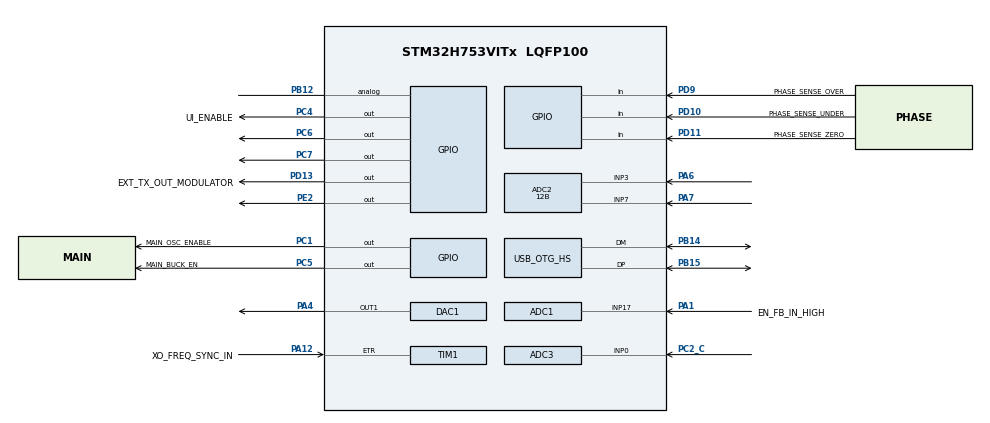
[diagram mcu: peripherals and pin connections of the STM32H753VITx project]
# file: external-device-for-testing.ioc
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ADC1.Channel-0\#ChannelRegularConversion=ADC_CHANNEL_17
ADC1.ClockPrescaler=ADC_CLOCK_SYNC_PCLK_DIV4
ADC1.ContinuousConvMode=DISABLE
ADC1.ConversionDataManagement=ADC_CONVERSIONDATA_DMA_CIRCULAR
ADC1.ExternalTrigConv=ADC_EXTERNALTRIG_T1_CC1
ADC1.ExternalTrigConvEdge=ADC_EXTERNALTRIGCONVEDGE_RISINGFALLING
ADC1.NbrOfConversionFlag=1
ADC1.OffsetNumber-0\#ChannelRegularConversion=ADC_OFFSET_NONE
ADC1.OffsetSignedSaturation-0\#ChannelRegularConversion=DISABLE
ADC1.Rank-0\#ChannelRegularConversion=1
ADC1.Resolution=ADC_RESOLUTION_12B
ADC1.SamplingTime-0\#ChannelRegularConversion=ADC_SAMPLETIME_1CYCLE_5
ADC1.master=1
ADC2.Channel-0\#ChannelRegularConversion=ADC_CHANNEL_7
ADC2.Channel-1\#ChannelRegularConversion=ADC_CHANNEL_3
ADC2.ClockPrescaler=ADC_CLOCK_SYNC_PCLK_DIV4
ADC2.ContinuousConvMode=ENABLE
ADC2.ConversionDataManagement=ADC_CONVERSIONDATA_DMA_CIRCULAR
ADC2.EOCSelection=ADC_EOC_SEQ_CONV
ADC2.NbrOfConversion=2
ADC2.NbrOfConversionFlag=1
ADC2.OffsetNumber-0\#ChannelRegularConversion=ADC_OFFSET_NONE
ADC2.OffsetNumber-1\#ChannelRegularConversion=ADC_OFFSET_NONE
ADC2.OffsetSignedSaturation-0\#ChannelRegularConversion=DISABLE
ADC2.Rank-0\#ChannelRegularConversion=1
ADC2.Rank-1\#ChannelRegularConversion=2
ADC2.Resolution=ADC_RESOLUTION_12B
ADC2.SamplingTime-0\#ChannelRegularConversion=ADC_SAMPLETIME_387CYCLES_5
ADC2.SamplingTime-1\#ChannelRegularConversion=ADC_SAMPLETIME_2CYCLES_5
ADC3.Channel-2\#ChannelRegularConversion=ADC_CHANNEL_0
ADC3.ClockPrescaler=ADC_CLOCK_SYNC_PCLK_DIV4
ADC3.NbrOfConversionFlag=1
ADC3.OffsetNumber-2\#ChannelRegularConversion=ADC_OFFSET_NONE
ADC3.OffsetSignedSaturation-2\#ChannelRegularConversion=DISABLE
ADC3.Rank-2\#ChannelRegularConversion=1
ADC3.SamplingTime-2\#ChannelRegularConversion=ADC_SAMPLETIME_1CYCLE_5
DAC1.DAC_Channel-DAC_OUT1=DAC_CHANNEL_1
Dma.ADC1.0.Direction=DMA_PERIPH_TO_MEMORY
Dma.ADC1.0.EventEnable=DISABLE
Dma.ADC1.0.FIFOMode=DMA_FIFOMODE_DISABLE
Dma.ADC1.0.Instance=DMA2_Stream4
Dma.ADC1.0.MemDataAlignment=DMA_MDATAALIGN_HALFWORD
Dma.ADC1.0.MemInc=DMA_MINC_ENABLE
Dma.ADC1.0.Mode=DMA_CIRCULAR
Dma.ADC1.0.PeriphDataAlignment=DMA_PDATAALIGN_HALFWORD
Dma.ADC1.0.PeriphInc=DMA_PINC_DISABLE
Dma.ADC1.0.Polarity=HAL_DMAMUX_REQ_GEN_RISING
Dma.ADC1.0.Priority=DMA_PRIORITY_LOW
Dma.ADC1.0.RequestNumber=1
Dma.ADC1.0.SignalID=NONE
Dma.ADC1.0.SyncEnable=DISABLE
Dma.ADC1.0.SyncPolarity=HAL_DMAMUX_SYNC_NO_EVENT
Dma.ADC1.0.SyncRequestNumber=1
Dma.ADC1.0.SyncSignalID=NONE
Dma.ADC2.1.Direction=DMA_PERIPH_TO_MEMORY
Dma.ADC2.1.EventEnable=DISABLE
Dma.ADC2.1.FIFOMode=DMA_FIFOMODE_DISABLE
Dma.ADC2.1.Instance=DMA2_Stream3
Dma.ADC2.1.MemDataAlignment=DMA_MDATAALIGN_HALFWORD
Dma.ADC2.1.MemInc=DMA_MINC_ENABLE
Dma.ADC2.1.Mode=DMA_CIRCULAR
Dma.ADC2.1.PeriphDataAlignment=DMA_PDATAALIGN_HALFWORD
Dma.ADC2.1.PeriphInc=DMA_PINC_DISABLE
Dma.ADC2.1.Polarity=HAL_DMAMUX_REQ_GEN_RISING
Dma.ADC2.1.Priority=DMA_PRIORITY_LOW
Dma.ADC2.1.RequestNumber=1
Dma.ADC2.1.SignalID=NONE
Dma.ADC2.1.SyncEnable=DISABLE
Dma.ADC2.1.SyncPolarity=HAL_DMAMUX_SYNC_NO_EVENT
Dma.ADC2.1.SyncRequestNumber=1
Dma.ADC2.1.SyncSignalID=NONE
Dma.Request0=ADC1
Dma.Request1=ADC2
FREERTOS.Tasks01=defaultTask,24,260,StartDefaultTask,Default,NULL,Dynamic,NULL,NULL
FREERTOS.configCHECK_FOR_STACK_OVERFLOW=1
FREERTOS.configMINIMAL_STACK_SIZE=260
FREERTOS.configTOTAL_HEAP_SIZE=53000
FREERTOS.configUSE_IDLE_HOOK=1
FREERTOS.configUSE_NEWLIB_REENTRANT=1
Mcu.Family=STM32H7
Mcu.Name=STM32H753VITx
Mcu.Package=LQFP100
NVIC.DMA2_Stream3_IRQn=true\:5\:0\:true\:false\:true\:false\:false\:true\:true
NVIC.DMA2_Stream4_IRQn=true\:5\:0\:true\:false\:true\:false\:false\:true\:true
NVIC.OTG_HS_IRQn=true\:5\:0\:false\:false\:true\:true\:true\:true\:true
NVIC.PVD_AVD_IRQn=true\:5\:0\:false\:false\:true\:true\:true\:true\:true
NVIC.PriorityGroup=NVIC_PRIORITYGROUP_4
NVIC.RTC_WKUP_IRQn=true\:5\:0\:false\:false\:true\:true\:true\:true\:true
NVIC.TIM1_BRK_IRQn=true\:5\:0\:false\:false\:true\:true\:true\:true\:true
NVIC.TIM1_CC_IRQn=true\:5\:0\:false\:false\:true\:true\:true\:true\:true
NVIC.TIM1_TRG_COM_IRQn=true\:5\:0\:false\:false\:true\:true\:true\:true\:true
NVIC.TIM1_UP_IRQn=true\:5\:0\:false\:false\:true\:true\:true\:true\:true
NVIC.TIM6_DAC_IRQn=true\:5\:0\:false\:false\:true\:true\:true\:true\:true
NVIC.TIM7_IRQn=true\:5\:0\:false\:false\:true\:true\:true\:true\:true
PA1.GPIO_Label=EN_FB_IN_HIGH
PA1.Mode=IN17-Single-Ended
PA1.Signal=ADC1_INP17
PA12.GPIO_Label=XO_FREQ_SYNC_IN
PA12.Signal=S_TIM1_ETR
PA13\ (JTMS/SWDIO).GPIO_Label=SYS_JTMS-SWDIO
PA13\ (JTMS/SWDIO).Mode=Serial_Wire
PA13\ (JTMS/SWDIO).Signal=DEBUG_JTMS-SWDIO
PA14\ (JTCK/SWCLK).GPIO_Label=SYS_JTCK-SWCLK
PA14\ (JTCK/SWCLK).Mode=Serial_Wire
PA14\ (JTCK/SWCLK).Signal=DEBUG_JTCK-SWCLK
PA4.Signal=COMP_DAC11_group
PA6.Signal=ADCx_INP3
PA7.Signal=ADCx_INP7
PB12.Signal=GPIO_Analog
PB14.GPIO_Speed=GPIO_SPEED_FREQ_VERY_HIGH
PB14.Mode=Device_Only_FS
PB14.Signal=USB_OTG_HS_DM
PB15.GPIO_Speed=GPIO_SPEED_FREQ_VERY_HIGH
PB15.Mode=Device_Only_FS
PB15.Signal=USB_OTG_HS_DP
PC1.GPIO_Label=MAIN_OSC_ENABLE
PC1.PinState=GPIO_PIN_SET
PC1.Signal=GPIO_Output
PC14-OSC32_IN\ (OSC32_IN).Mode=LSE-External-Oscillator
PC14-OSC32_IN\ (OSC32_IN).Signal=RCC_OSC32_IN
PC15-OSC32_OUT\ (OSC32_OUT).Mode=LSE-External-Oscillator
PC15-OSC32_OUT\ (OSC32_OUT).Signal=RCC_OSC32_OUT
PC2_C.Mode=IN0-Single-Ended
PC2_C.Signal=ADC3_INP0
PC4.GPIO_Label=UI_ENABLE
PC4.Signal=GPIO_Output
PC5.GPIO_Label=MAIN_BUCK_EN
PC5.Signal=GPIO_Output
PC6.Signal=GPIO_Output
PC7.Signal=GPIO_Output
PD10.GPIO_Label=PHASE_SENSE_UNDER
PD10.Signal=GPIO_Input
PD11.GPIO_Label=PHASE_SENSE_ZERO
PD11.Signal=GPIO_Input
PD13.GPIO_Label=EXT_TX_OUT_MODULATOR
PD13.Signal=GPIO_Output
PD9.GPIO_Label=PHASE_SENSE_OVER
PD9.Signal=GPIO_Input
PE2.Signal=GPIO_Output
PH0-OSC_IN\ (PH0).Mode=HSE-External-Oscillator
PH0-OSC_IN\ (PH0).Signal=RCC_OSC_IN
PH1-OSC_OUT\ (PH1).Mode=HSE-External-Oscillator
PH1-OSC_OUT\ (PH1).Signal=RCC_OSC_OUT
ProjectManager.HeapSize=0x200
ProjectManager.StackSize=0x1000
ProjectManager.TargetToolchain=STM32CubeIDE
RCC.ADCFreq_Value=48000000
RCC.APB1Freq_Value=36000000
RCC.APB2Freq_Value=72000000
RCC.APB3Freq_Value=72000000
RCC.APB4Freq_Value=72000000
RCC.CortexFreq_Value=72000000
RCC.D2PPRE1=RCC_APB1_DIV2
RCC.DIVM1=4
RCC.DIVM2=4
RCC.DIVN1=144
RCC.DIVN2=144
RCC.DIVP1=4
RCC.DIVP2=6
RCC.DIVQ1=6
RCC.DIVQ2=8
RCC.HCLKFreq_Value=72000000
RCC.HSE_VALUE=8000000
RCC.PLL2FRACN=0
RCC.PLL3FRACN=0
RCC.PLLFRACN=0
RCC.PLLSourceVirtual=RCC_PLLSOURCE_HSE
RCC.SYSCLKFreq_VALUE=72000000
RCC.SYSCLKSource=RCC_SYSCLKSOURCE_PLLCLK
RCC.Tim2Mul=1
RCC.USART16CLockSelection=RCC_USART16CLKSOURCE_PLL2
RCC.USBFreq_Value=48000000
SH.ADCx_INP3.0=ADC2_INP3,IN3-Single-Ended
SH.ADCx_INP7.0=ADC2_INP7,IN7-Single-Ended
SH.COMP_DAC11_group.0=DAC1_OUT1,DAC_OUT1
SH.S_TIM1_ETR.0=TIM1_ETR,TriggerSource_ETR
TIM1.AutoReloadPreload=TIM_AUTORELOAD_PRELOAD_ENABLE
TIM1.Channel-Output\ Compare1\ No\ Output=TIM_CHANNEL_1
TIM1.OC1Preload=ENABLE
TIM1.OCMode_1=TIM_OCMODE_TOGGLE
TIM1.Period=31
TIM1.Pulse-Output\ Compare1\ No\ Output=16
TIM1.TIM_MasterOutputTrigger=TIM_TRGO_OC1REF
TIM1.TIM_MasterSlaveMode=TIM_MASTERSLAVEMODE_ENABLE
TIM2.AutoReloadPreload=TIM_AUTORELOAD_PRELOAD_ENABLE
TIM2.Channel-PWM\ Generation4\ CH4=TIM_CHANNEL_4
TIM2.Period=100
TIM2.Prescaler=36
TIM2.TIM_MasterOutputTrigger=TIM_TRGO_UPDATE
TIM5.AutoReloadPreload=TIM_AUTORELOAD_PRELOAD_ENABLE
TIM5.Period=10
TIM5.Prescaler=36
TIM7.Period=10000
TIM7.Prescaler=4
USB_DEVICE.APP_RX_DATA_SIZE-CDC_HS=2048
USB_DEVICE.APP_TX_DATA_SIZE-CDC_HS=2048
USB_DEVICE.CLASS_NAME_HS=CDC
USB_DEVICE.VirtualMode-CDC_HS=Cdc
USB_DEVICE.VirtualModeHS=Cdc_HS
USB_OTG_HS.VirtualMode-Device_Only_FS=Device_Only_FS
USB_OTG_HS.dma_enable-Device_Only_FS=DISABLE
VP_FREERTOS_VS_CMSIS_V2.Mode=CMSIS_V2
VP_MEMORYMAP_VS_MEMORYMAP.Mode=CurAppReg
VP_RTC_VS_RTC_Activate.Mode=RTC_Enabled
VP_RTC_VS_RTC_Calendar.Mode=RTC_Calendar
VP_RTC_VS_RTC_WakeUp_intern.Mode=WakeUp
VP_TIM1_VS_ControllerModeClock.Mode=Clock Mode
VP_TIM1_VS_no_output1.Mode=Output Compare1 No Output
VP_TIM2_VS_ClockSourceINT.Mode=Internal
VP_TIM5_VS_ClockSourceINT.Mode=Internal
VP_TIM6_VS_ClockSourceINT.Mode=Enable_Timer
VP_TIM7_VS_ClockSourceINT.Mode=Enable_Timer
VP_USB_DEVICE_VS_USB_DEVICE_CDC_HS.Mode=CDC_HS
board=custom

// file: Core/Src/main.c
/* USER CODE BEGIN Header */
/**
 ******************************************************************************
 * @file           : main.c
 * @brief          : Main program body
 ******************************************************************************
 * @attention
 *
 * Copyright (c) 2025 STMicroelectronics.
 * All rights reserved.
 *
 * This software is licensed under terms that can be found in the LICENSE file
 * in the root directory of this software component.
 * If no LICENSE file comes with this software, it is provided AS-IS.
 *
 ******************************************************************************
 */
/* USER CODE END Header */
#include "main.h"
#include "cmsis_os.h"
#include "usb_device.h"

/* USER CODE BEGIN Includes */
#include "vlapMain.h"
/* USER CODE END Includes */

ADC_HandleTypeDef hadc1;
ADC_HandleTypeDef hadc2;
ADC_HandleTypeDef hadc3;
DMA_HandleTypeDef hdma_adc1;
DMA_HandleTypeDef hdma_adc2;

DAC_HandleTypeDef hdac1;

RTC_HandleTypeDef hrtc;

TIM_HandleTypeDef htim1;
TIM_HandleTypeDef htim2;
TIM_HandleTypeDef htim5;
TIM_HandleTypeDef htim6;
TIM_HandleTypeDef htim7;

/* Definitions for defaultTask */
osThreadId_t defaultTaskHandle;
const osThreadAttr_t defaultTask_attributes = {
  .name = "defaultTask",
  .stack_size = 260 * 4,
  .priority = (osPriority_t) osPriorityNormal,
};

void SystemClock_Config(void);
static void MX_GPIO_Init(void);
static void MX_DMA_Init(void);
static void MX_RTC_Init(void);
static void MX_ADC1_Init(void);
static void MX_TIM1_Init(void);
static void MX_TIM2_Init(void);
static void MX_TIM5_Init(void);
static void MX_TIM6_Init(void);
static void MX_TIM7_Init(void);
static void MX_ADC3_Init(void);
static void MX_ADC2_Init(void);
static void MX_DAC1_Init(void);
void StartDefaultTask(void *argument);

/* USER CODE BEGIN 0 */
uint8_t mainFirstTimeAfterJlinkProgramming;
/* USER CODE END 0 */

int main(void)
{

  /* USER CODE BEGIN 1 */
	// We need to enable the external 27.12Mhz generator first before we init clocks
//	SCB->VTOR = FLASH_BASE | (0x0000C000U & (uint32_t) 0x1FFFFF80); /* Vector Table Relocation in Internal SRAM */
	HAL_Init();
	MX_GPIO_Init();
  /* USER CODE END 1 */

  /* MCU Configuration--------------------------------------------------------*/

  /* Reset of all peripherals, Initializes the Flash interface and the Systick. */
  HAL_Init();

  /* Configure the system clock */
  SystemClock_Config();

  /* Initialize all configured peripherals */
  MX_GPIO_Init();
  MX_DMA_Init();
  MX_RTC_Init();
  MX_ADC1_Init();
  MX_TIM1_Init();
  MX_TIM2_Init();
  MX_TIM5_Init();
  MX_TIM6_Init();
  MX_TIM7_Init();
  MX_ADC3_Init();
  MX_ADC2_Init();
  MX_DAC1_Init();
  /* USER CODE BEGIN 2 */

	protocolappPowerUpInit();

	vlapMainBusy = 1;
	vlapMainSetupHardware(mainFirstTimeAfterJlinkProgramming);

	mainFirstTimeAfterJlinkProgramming = 0;

	// create vlapMainTask
	//
	xTaskCreate(vlapMain, vlapMainName, vlapMainSTACK_SIZE, NULL,
			vlapMainPriority, (TaskHandle_t*) NULL);

	// Clear the reset reason for coming
	__HAL_RCC_CLEAR_RESET_FLAGS();

  /* USER CODE END 2 */

  /* Init scheduler */
  osKernelInitialize();

  /* Create the thread(s) */
  /* creation of defaultTask */
  defaultTaskHandle = osThreadNew(StartDefaultTask, NULL, &defaultTask_attributes);

  /* Start scheduler */
  osKernelStart();

  /* We should never get here as control is now taken by the scheduler */

  /* Infinite loop */
	while (1) {

	}
}

void SystemClock_Config(void)
{
  RCC_OscInitTypeDef RCC_OscInitStruct = {0};
  RCC_ClkInitTypeDef RCC_ClkInitStruct = {0};

  /** Supply configuration update enable
  */
  HAL_PWREx_ConfigSupply(PWR_LDO_SUPPLY);

  /** Configure the main internal regulator output voltage
  */
  __HAL_PWR_VOLTAGESCALING_CONFIG(PWR_REGULATOR_VOLTAGE_SCALE3);

  while(!__HAL_PWR_GET_FLAG(PWR_FLAG_VOSRDY)) {}

  /** Initializes the RCC Oscillators according to the specified parameters
  * in the RCC_OscInitTypeDef structure.
  */
  RCC_OscInitStruct.OscillatorType = RCC_OSCILLATORTYPE_LSI|RCC_OSCILLATORTYPE_HSE;
  RCC_OscInitStruct.HSEState = RCC_HSE_ON;
  RCC_OscInitStruct.LSIState = RCC_LSI_ON;
  RCC_OscInitStruct.PLL.PLLState = RCC_PLL_ON;
  RCC_OscInitStruct.PLL.PLLSource = RCC_PLLSOURCE_HSE;
  RCC_OscInitStruct.PLL.PLLM = 4;
  RCC_OscInitStruct.PLL.PLLN = 144;
  RCC_OscInitStruct.PLL.PLLP = 4;
  RCC_OscInitStruct.PLL.PLLQ = 6;
  RCC_OscInitStruct.PLL.PLLR = 2;
  RCC_OscInitStruct.PLL.PLLRGE = RCC_PLL1VCIRANGE_1;
  RCC_OscInitStruct.PLL.PLLVCOSEL = RCC_PLL1VCOWIDE;
  RCC_OscInitStruct.PLL.PLLFRACN = 0;
  if (HAL_RCC_OscConfig(&RCC_OscInitStruct) != HAL_OK)
  {
    Error_Handler();
  }

  /** Initializes the CPU, AHB and APB buses clocks
  */
  RCC_ClkInitStruct.ClockType = RCC_CLOCKTYPE_HCLK|RCC_CLOCKTYPE_SYSCLK
                              |RCC_CLOCKTYPE_PCLK1|RCC_CLOCKTYPE_PCLK2
                              |RCC_CLOCKTYPE_D3PCLK1|RCC_CLOCKTYPE_D1PCLK1;
  RCC_ClkInitStruct.SYSCLKSource = RCC_SYSCLKSOURCE_PLLCLK;
  RCC_ClkInitStruct.SYSCLKDivider = RCC_SYSCLK_DIV1;
  RCC_ClkInitStruct.AHBCLKDivider = RCC_HCLK_DIV1;
  RCC_ClkInitStruct.APB3CLKDivider = RCC_APB3_DIV1;
  RCC_ClkInitStruct.APB1CLKDivider = RCC_APB1_DIV2;
  RCC_ClkInitStruct.APB2CLKDivider = RCC_APB2_DIV1;
  RCC_ClkInitStruct.APB4CLKDivider = RCC_APB4_DIV1;

  if (HAL_RCC_ClockConfig(&RCC_ClkInitStruct, FLASH_LATENCY_1) != HAL_OK)
  {
    Error_Handler();
  }
}

static void MX_ADC1_Init(void)
{

  ADC_MultiModeTypeDef multimode = {0};
  ADC_ChannelConfTypeDef sConfig = {0};

  /** Common config
  */
  hadc1.Instance = ADC1;
  hadc1.Init.ClockPrescaler = ADC_CLOCK_SYNC_PCLK_DIV4;
  hadc1.Init.Resolution = ADC_RESOLUTION_12B;
  hadc1.Init.ScanConvMode = ADC_SCAN_DISABLE;
  hadc1.Init.EOCSelection = ADC_EOC_SINGLE_CONV;
  hadc1.Init.LowPowerAutoWait = DISABLE;
  hadc1.Init.ContinuousConvMode = DISABLE;
  hadc1.Init.NbrOfConversion = 1;
  hadc1.Init.DiscontinuousConvMode = DISABLE;
  hadc1.Init.ExternalTrigConv = ADC_EXTERNALTRIG_T1_CC1;
  hadc1.Init.ExternalTrigConvEdge = ADC_EXTERNALTRIGCONVEDGE_RISINGFALLING;
  hadc1.Init.ConversionDataManagement = ADC_CONVERSIONDATA_DMA_CIRCULAR;
  hadc1.Init.Overrun = ADC_OVR_DATA_PRESERVED;
  hadc1.Init.LeftBitShift = ADC_LEFTBITSHIFT_NONE;
  hadc1.Init.OversamplingMode = DISABLE;
  hadc1.Init.Oversampling.Ratio = 1;
  if (HAL_ADC_Init(&hadc1) != HAL_OK)
  {
    Error_Handler();
  }

  /** Configure the ADC multi-mode
  */
  multimode.Mode = ADC_MODE_INDEPENDENT;
  if (HAL_ADCEx_MultiModeConfigChannel(&hadc1, &multimode) != HAL_OK)
  {
    Error_Handler();
  }

  /** Configure Regular Channel
  */
  sConfig.Channel = ADC_CHANNEL_17;
  sConfig.Rank = ADC_REGULAR_RANK_1;
  sConfig.SamplingTime = ADC_SAMPLETIME_1CYCLE_5;
  sConfig.SingleDiff = ADC_SINGLE_ENDED;
  sConfig.OffsetNumber = ADC_OFFSET_NONE;
  sConfig.Offset = 0;
  sConfig.OffsetSignedSaturation = DISABLE;
  if (HAL_ADC_ConfigChannel(&hadc1, &sConfig) != HAL_OK)
  {
    Error_Handler();
  }

}

static void MX_ADC2_Init(void)
{

  ADC_ChannelConfTypeDef sConfig = {0};

  /** Common config
  */
  hadc2.Instance = ADC2;
  hadc2.Init.ClockPrescaler = ADC_CLOCK_SYNC_PCLK_DIV4;
  hadc2.Init.Resolution = ADC_RESOLUTION_12B;
  hadc2.Init.ScanConvMode = ADC_SCAN_ENABLE;
  hadc2.Init.EOCSelection = ADC_EOC_SEQ_CONV;
  hadc2.Init.LowPowerAutoWait = DISABLE;
  hadc2.Init.ContinuousConvMode = ENABLE;
  hadc2.Init.NbrOfConversion = 2;
  hadc2.Init.DiscontinuousConvMode = DISABLE;
  hadc2.Init.ExternalTrigConv = ADC_SOFTWARE_START;
  hadc2.Init.ExternalTrigConvEdge = ADC_EXTERNALTRIGCONVEDGE_NONE;
  hadc2.Init.ConversionDataManagement = ADC_CONVERSIONDATA_DMA_CIRCULAR;
  hadc2.Init.Overrun = ADC_OVR_DATA_PRESERVED;
  hadc2.Init.LeftBitShift = ADC_LEFTBITSHIFT_NONE;
  hadc2.Init.OversamplingMode = DISABLE;
  hadc2.Init.Oversampling.Ratio = 1;
  if (HAL_ADC_Init(&hadc2) != HAL_OK)
  {
    Error_Handler();
  }

  /** Configure Regular Channel
  */
  sConfig.Channel = ADC_CHANNEL_7;
  sConfig.Rank = ADC_REGULAR_RANK_1;
  sConfig.SamplingTime = ADC_SAMPLETIME_387CYCLES_5;
  sConfig.SingleDiff = ADC_SINGLE_ENDED;
  sConfig.OffsetNumber = ADC_OFFSET_NONE;
  sConfig.Offset = 0;
  sConfig.OffsetSignedSaturation = DISABLE;
  if (HAL_ADC_ConfigChannel(&hadc2, &sConfig) != HAL_OK)
  {
    Error_Handler();
  }

  /** Configure Regular Channel
  */
  sConfig.Channel = ADC_CHANNEL_3;
  sConfig.Rank = ADC_REGULAR_RANK_2;
  sConfig.SamplingTime = ADC_SAMPLETIME_2CYCLES_5;
  if (HAL_ADC_ConfigChannel(&hadc2, &sConfig) != HAL_OK)
  {
    Error_Handler();
  }

}

static void MX_ADC3_Init(void)
{

  ADC_ChannelConfTypeDef sConfig = {0};

  /** Common config
  */
  hadc3.Instance = ADC3;
  hadc3.Init.ClockPrescaler = ADC_CLOCK_ASYNC_DIV1;
  hadc3.Init.ScanConvMode = ADC_SCAN_DISABLE;
  hadc3.Init.EOCSelection = ADC_EOC_SINGLE_CONV;
  hadc3.Init.LowPowerAutoWait = DISABLE;
  hadc3.Init.ContinuousConvMode = DISABLE;
  hadc3.Init.NbrOfConversion = 1;
  hadc3.Init.DiscontinuousConvMode = DISABLE;
  hadc3.Init.ExternalTrigConv = ADC_SOFTWARE_START;
  hadc3.Init.ExternalTrigConvEdge = ADC_EXTERNALTRIGCONVEDGE_NONE;
  hadc3.Init.ConversionDataManagement = ADC_CONVERSIONDATA_DR;
  hadc3.Init.Overrun = ADC_OVR_DATA_PRESERVED;
  hadc3.Init.LeftBitShift = ADC_LEFTBITSHIFT_NONE;
  hadc3.Init.OversamplingMode = DISABLE;
  hadc3.Init.Oversampling.Ratio = 1;
  if (HAL_ADC_Init(&hadc3) != HAL_OK)
  {
    Error_Handler();
  }

  /** Configure Regular Channel
  */
  sConfig.Channel = ADC_CHANNEL_0;
  sConfig.Rank = ADC_REGULAR_RANK_1;
  sConfig.SamplingTime = ADC_SAMPLETIME_1CYCLE_5;
  sConfig.SingleDiff = ADC_SINGLE_ENDED;
  sConfig.OffsetNumber = ADC_OFFSET_NONE;
  sConfig.Offset = 0;
  sConfig.OffsetSignedSaturation = DISABLE;
  if (HAL_ADC_ConfigChannel(&hadc3, &sConfig) != HAL_OK)
  {
    Error_Handler();
  }

}

static void MX_DAC1_Init(void)
{

  DAC_ChannelConfTypeDef sConfig = {0};

  /** DAC Initialization
  */
  hdac1.Instance = DAC1;
  if (HAL_DAC_Init(&hdac1) != HAL_OK)
  {
    Error_Handler();
  }

  /** DAC channel OUT1 config
  */
  sConfig.DAC_SampleAndHold = DAC_SAMPLEANDHOLD_DISABLE;
  sConfig.DAC_Trigger = DAC_TRIGGER_NONE;
  sConfig.DAC_OutputBuffer = DAC_OUTPUTBUFFER_ENABLE;
  sConfig.DAC_ConnectOnChipPeripheral = DAC_CHIPCONNECT_DISABLE;
  sConfig.DAC_UserTrimming = DAC_TRIMMING_FACTORY;
  if (HAL_DAC_ConfigChannel(&hdac1, &sConfig, DAC_CHANNEL_1) != HAL_OK)
  {
    Error_Handler();
  }

}

static void MX_RTC_Init(void)
{

  RTC_TimeTypeDef sTime = {0};
  RTC_DateTypeDef sDate = {0};

  /** Initialize RTC Only
  */
  hrtc.Instance = RTC;
  hrtc.Init.HourFormat = RTC_HOURFORMAT_24;
  hrtc.Init.AsynchPrediv = 127;
  hrtc.Init.SynchPrediv = 255;
  hrtc.Init.OutPut = RTC_OUTPUT_DISABLE;
  hrtc.Init.OutPutPolarity = RTC_OUTPUT_POLARITY_HIGH;
  hrtc.Init.OutPutType = RTC_OUTPUT_TYPE_OPENDRAIN;
  hrtc.Init.OutPutRemap = RTC_OUTPUT_REMAP_NONE;
  if (HAL_RTC_Init(&hrtc) != HAL_OK)
  {
    Error_Handler();
  }

  /** Initialize RTC and set the Time and Date
  */
  sTime.Hours = 0x0;
  sTime.Minutes = 0x0;
  sTime.Seconds = 0x0;
  sTime.DayLightSaving = RTC_DAYLIGHTSAVING_NONE;
  sTime.StoreOperation = RTC_STOREOPERATION_RESET;
  if (HAL_RTC_SetTime(&hrtc, &sTime, RTC_FORMAT_BCD) != HAL_OK)
  {
    Error_Handler();
  }
  sDate.WeekDay = RTC_WEEKDAY_MONDAY;
  sDate.Month = RTC_MONTH_JANUARY;
  sDate.Date = 0x1;
  sDate.Year = 0x0;

  if (HAL_RTC_SetDate(&hrtc, &sDate, RTC_FORMAT_BCD) != HAL_OK)
  {
    Error_Handler();
  }

  /** Enable the WakeUp
  */
  if (HAL_RTCEx_SetWakeUpTimer_IT(&hrtc, 0, RTC_WAKEUPCLOCK_RTCCLK_DIV16) != HAL_OK)
  {
    Error_Handler();
  }

}

static void MX_TIM1_Init(void)
{

  TIM_SlaveConfigTypeDef sSlaveConfig = {0};
  TIM_MasterConfigTypeDef sMasterConfig = {0};
  TIM_OC_InitTypeDef sConfigOC = {0};
  TIM_BreakDeadTimeConfigTypeDef sBreakDeadTimeConfig = {0};

  htim1.Instance = TIM1;
  htim1.Init.Prescaler = 0;
  htim1.Init.CounterMode = TIM_COUNTERMODE_UP;
  htim1.Init.Period = 31;
  htim1.Init.ClockDivision = TIM_CLOCKDIVISION_DIV1;
  htim1.Init.RepetitionCounter = 0;
  htim1.Init.AutoReloadPreload = TIM_AUTORELOAD_PRELOAD_ENABLE;
  if (HAL_TIM_Base_Init(&htim1) != HAL_OK)
  {
    Error_Handler();
  }
  if (HAL_TIM_OC_Init(&htim1) != HAL_OK)
  {
    Error_Handler();
  }
  sSlaveConfig.SlaveMode = TIM_SLAVEMODE_EXTERNAL1;
  sSlaveConfig.InputTrigger = TIM_TS_ETRF;
  sSlaveConfig.TriggerPolarity = TIM_TRIGGERPOLARITY_NONINVERTED;
  sSlaveConfig.TriggerPrescaler = TIM_TRIGGERPRESCALER_DIV1;
  sSlaveConfig.TriggerFilter = 0;
  if (HAL_TIM_SlaveConfigSynchro(&htim1, &sSlaveConfig) != HAL_OK)
  {
    Error_Handler();
  }
  sMasterConfig.MasterOutputTrigger = TIM_TRGO_OC1REF;
  sMasterConfig.MasterOutputTrigger2 = TIM_TRGO2_RESET;
  sMasterConfig.MasterSlaveMode = TIM_MASTERSLAVEMODE_ENABLE;
  if (HAL_TIMEx_MasterConfigSynchronization(&htim1, &sMasterConfig) != HAL_OK)
  {
    Error_Handler();
  }
  sConfigOC.OCMode = TIM_OCMODE_TOGGLE;
  sConfigOC.Pulse = 16;
  sConfigOC.OCPolarity = TIM_OCPOLARITY_HIGH;
  sConfigOC.OCNPolarity = TIM_OCNPOLARITY_HIGH;
  sConfigOC.OCFastMode = TIM_OCFAST_DISABLE;
  sConfigOC.OCIdleState = TIM_OCIDLESTATE_RESET;
  sConfigOC.OCNIdleState = TIM_OCNIDLESTATE_RESET;
  if (HAL_TIM_OC_ConfigChannel(&htim1, &sConfigOC, TIM_CHANNEL_1) != HAL_OK)
  {
    Error_Handler();
  }
  __HAL_TIM_ENABLE_OCxPRELOAD(&htim1, TIM_CHANNEL_1);
  sBreakDeadTimeConfig.OffStateRunMode = TIM_OSSR_DISABLE;
  sBreakDeadTimeConfig.OffStateIDLEMode = TIM_OSSI_DISABLE;
  sBreakDeadTimeConfig.LockLevel = TIM_LOCKLEVEL_OFF;
  sBreakDeadTimeConfig.DeadTime = 0;
  sBreakDeadTimeConfig.BreakState = TIM_BREAK_DISABLE;
  sBreakDeadTimeConfig.BreakPolarity = TIM_BREAKPOLARITY_HIGH;
  sBreakDeadTimeConfig.BreakFilter = 0;
  sBreakDeadTimeConfig.Break2State = TIM_BREAK2_DISABLE;
  sBreakDeadTimeConfig.Break2Polarity = TIM_BREAK2POLARITY_HIGH;
  sBreakDeadTimeConfig.Break2Filter = 0;
  sBreakDeadTimeConfig.AutomaticOutput = TIM_AUTOMATICOUTPUT_DISABLE;
  if (HAL_TIMEx_ConfigBreakDeadTime(&htim1, &sBreakDeadTimeConfig) != HAL_OK)
  {
    Error_Handler();
  }

}

static void MX_TIM2_Init(void)
{

  TIM_ClockConfigTypeDef sClockSourceConfig = {0};
  TIM_MasterConfigTypeDef sMasterConfig = {0};

  htim2.Instance = TIM2;
  htim2.Init.Prescaler = 36;
  htim2.Init.CounterMode = TIM_COUNTERMODE_UP;
  htim2.Init.Period = 100;
  htim2.Init.ClockDivision = TIM_CLOCKDIVISION_DIV1;
  htim2.Init.AutoReloadPreload = TIM_AUTORELOAD_PRELOAD_ENABLE;
  if (HAL_TIM_Base_Init(&htim2) != HAL_OK)
  {
    Error_Handler();
  }
  sClockSourceConfig.ClockSource = TIM_CLOCKSOURCE_INTERNAL;
  if (HAL_TIM_ConfigClockSource(&htim2, &sClockSourceConfig) != HAL_OK)
  {
    Error_Handler();
  }
  sMasterConfig.MasterOutputTrigger = TIM_TRGO_UPDATE;
  sMasterConfig.MasterSlaveMode = TIM_MASTERSLAVEMODE_DISABLE;
  if (HAL_TIMEx_MasterConfigSynchronization(&htim2, &sMasterConfig) != HAL_OK)
  {
    Error_Handler();
  }

}

static void MX_TIM5_Init(void)
{

  TIM_ClockConfigTypeDef sClockSourceConfig = {0};
  TIM_MasterConfigTypeDef sMasterConfig = {0};

  htim5.Instance = TIM5;
  htim5.Init.Prescaler = 36;
  htim5.Init.CounterMode = TIM_COUNTERMODE_UP;
  htim5.Init.Period = 10;
  htim5.Init.ClockDivision = TIM_CLOCKDIVISION_DIV1;
  htim5.Init.AutoReloadPreload = TIM_AUTORELOAD_PRELOAD_ENABLE;
  if (HAL_TIM_Base_Init(&htim5) != HAL_OK)
  {
    Error_Handler();
  }
  sClockSourceConfig.ClockSource = TIM_CLOCKSOURCE_INTERNAL;
  if (HAL_TIM_ConfigClockSource(&htim5, &sClockSourceConfig) != HAL_OK)
  {
    Error_Handler();
  }
  sMasterConfig.MasterOutputTrigger = TIM_TRGO_RESET;
  sMasterConfig.MasterSlaveMode = TIM_MASTERSLAVEMODE_DISABLE;
  if (HAL_TIMEx_MasterConfigSynchronization(&htim5, &sMasterConfig) != HAL_OK)
  {
    Error_Handler();
  }

}

static void MX_TIM6_Init(void)
{

  TIM_MasterConfigTypeDef sMasterConfig = {0};

  htim6.Instance = TIM6;
  htim6.Init.Prescaler = 0;
  htim6.Init.CounterMode = TIM_COUNTERMODE_UP;
  htim6.Init.Period = 65535;
  htim6.Init.AutoReloadPreload = TIM_AUTORELOAD_PRELOAD_DISABLE;
  if (HAL_TIM_Base_Init(&htim6) != HAL_OK)
  {
    Error_Handler();
  }
  sMasterConfig.MasterOutputTrigger = TIM_TRGO_RESET;
  sMasterConfig.MasterSlaveMode = TIM_MASTERSLAVEMODE_DISABLE;
  if (HAL_TIMEx_MasterConfigSynchronization(&htim6, &sMasterConfig) != HAL_OK)
  {
    Error_Handler();
  }

}

static void MX_TIM7_Init(void)
{

  TIM_MasterConfigTypeDef sMasterConfig = {0};

  htim7.Instance = TIM7;
  htim7.Init.Prescaler = 4;
  htim7.Init.CounterMode = TIM_COUNTERMODE_UP;
  htim7.Init.Period = 10000;
  htim7.Init.AutoReloadPreload = TIM_AUTORELOAD_PRELOAD_DISABLE;
  if (HAL_TIM_Base_Init(&htim7) != HAL_OK)
  {
    Error_Handler();
  }
  sMasterConfig.MasterOutputTrigger = TIM_TRGO_RESET;
  sMasterConfig.MasterSlaveMode = TIM_MASTERSLAVEMODE_DISABLE;
  if (HAL_TIMEx_MasterConfigSynchronization(&htim7, &sMasterConfig) != HAL_OK)
  {
    Error_Handler();
  }

}

static void MX_DMA_Init(void)
{

  /* DMA controller clock enable */
  __HAL_RCC_DMA2_CLK_ENABLE();

  /* DMA interrupt init */
  /* DMA2_Stream3_IRQn interrupt configuration */
  HAL_NVIC_SetPriority(DMA2_Stream3_IRQn, 5, 0);
  HAL_NVIC_EnableIRQ(DMA2_Stream3_IRQn);
  /* DMA2_Stream4_IRQn interrupt configuration */
  HAL_NVIC_SetPriority(DMA2_Stream4_IRQn, 5, 0);
  HAL_NVIC_EnableIRQ(DMA2_Stream4_IRQn);

}

static void MX_GPIO_Init(void)
{
  GPIO_InitTypeDef GPIO_InitStruct = {0};

  /* GPIO Ports Clock Enable */
  __HAL_RCC_GPIOE_CLK_ENABLE();
  __HAL_RCC_GPIOC_CLK_ENABLE();
  __HAL_RCC_GPIOH_CLK_ENABLE();
  __HAL_RCC_GPIOA_CLK_ENABLE();
  __HAL_RCC_GPIOB_CLK_ENABLE();
  __HAL_RCC_GPIOD_CLK_ENABLE();

  /*Configure GPIO pin Output Level */
  HAL_GPIO_WritePin(GPIOE, GPIO_PIN_2, GPIO_PIN_RESET);

  /*Configure GPIO pin Output Level */
  HAL_GPIO_WritePin(MAIN_OSC_ENABLE_GPIO_Port, MAIN_OSC_ENABLE_Pin, GPIO_PIN_SET);

  /*Configure GPIO pin Output Level */
  HAL_GPIO_WritePin(GPIOC, UI_ENABLE_Pin|MAIN_BUCK_EN_Pin|GPIO_PIN_6|GPIO_PIN_7, GPIO_PIN_RESET);

  /*Configure GPIO pin Output Level */
  HAL_GPIO_WritePin(EXT_TX_OUT_MODULATOR_GPIO_Port, EXT_TX_OUT_MODULATOR_Pin, GPIO_PIN_RESET);

  /*Configure GPIO pin : PE2 */
  GPIO_InitStruct.Pin = GPIO_PIN_2;
  GPIO_InitStruct.Mode = GPIO_MODE_OUTPUT_PP;
  GPIO_InitStruct.Pull = GPIO_NOPULL;
  GPIO_InitStruct.Speed = GPIO_SPEED_FREQ_LOW;
  HAL_GPIO_Init(GPIOE, &GPIO_InitStruct);

  /*Configure GPIO pins : MAIN_OSC_ENABLE_Pin UI_ENABLE_Pin MAIN_BUCK_EN_Pin PC6
                           PC7 */
  GPIO_InitStruct.Pin = MAIN_OSC_ENABLE_Pin|UI_ENABLE_Pin|MAIN_BUCK_EN_Pin|GPIO_PIN_6
                          |GPIO_PIN_7;
  GPIO_InitStruct.Mode = GPIO_MODE_OUTPUT_PP;
  GPIO_InitStruct.Pull = GPIO_NOPULL;
  GPIO_InitStruct.Speed = GPIO_SPEED_FREQ_LOW;
  HAL_GPIO_Init(GPIOC, &GPIO_InitStruct);

  /*Configure GPIO pin : PB12 */
  GPIO_InitStruct.Pin = GPIO_PIN_12;
  GPIO_InitStruct.Mode = GPIO_MODE_ANALOG;
  GPIO_InitStruct.Pull = GPIO_NOPULL;
  HAL_GPIO_Init(GPIOB, &GPIO_InitStruct);

  /*Configure GPIO pins : PHASE_SENSE_OVER_Pin PHASE_SENSE_UNDER_Pin PHASE_SENSE_ZERO_Pin */
  GPIO_InitStruct.Pin = PHASE_SENSE_OVER_Pin|PHASE_SENSE_UNDER_Pin|PHASE_SENSE_ZERO_Pin;
  GPIO_InitStruct.Mode = GPIO_MODE_INPUT;
  GPIO_InitStruct.Pull = GPIO_NOPULL;
  HAL_GPIO_Init(GPIOD, &GPIO_InitStruct);

  /*Configure GPIO pin : EXT_TX_OUT_MODULATOR_Pin */
  GPIO_InitStruct.Pin = EXT_TX_OUT_MODULATOR_Pin;
  GPIO_InitStruct.Mode = GPIO_MODE_OUTPUT_PP;
  GPIO_InitStruct.Pull = GPIO_NOPULL;
  GPIO_InitStruct.Speed = GPIO_SPEED_FREQ_LOW;
  HAL_GPIO_Init(EXT_TX_OUT_MODULATOR_GPIO_Port, &GPIO_InitStruct);

}

/* USER CODE BEGIN 4 */
void HAL_TIM_PeriodElapsedCallback(TIM_HandleTypeDef *htim)
{
  /* USER CODE BEGIN Callback 0 */

  /* USER CODE END Callback 0 */
  if (htim->Instance == TIM6) {
    vmicmodemTim6Isr();
  }
  /* USER CODE BEGIN Callback 1 */

  /* USER CODE END Callback 1 */
}
/* USER CODE END 4 */

void StartDefaultTask(void *argument)
{
  /* init code for USB_DEVICE */
  MX_USB_DEVICE_Init();
	for (;;) {
		osDelay(1);
	}
}

void Error_Handler(void)
{
	__disable_irq();
	while (1) {
	}
}

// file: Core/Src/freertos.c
/* USER CODE BEGIN Header */
/**
  ******************************************************************************
  * File Name          : freertos.c
  * Description        : Code for freertos applications
  ******************************************************************************
  * @attention
  *
  * Copyright (c) 2025 STMicroelectronics.
  * All rights reserved.
  *
  * This software is licensed under terms that can be found in the LICENSE file
  * in the root directory of this software component.
  * If no LICENSE file comes with this software, it is provided AS-IS.
  *
  ******************************************************************************
  */
/* USER CODE END Header */

#include "FreeRTOS.h"
#include "task.h"
#include "main.h"

/* Hook prototypes */
void vApplicationIdleHook(void);
void vApplicationStackOverflowHook(xTaskHandle xTask, signed char *pcTaskName);

/* USER CODE BEGIN 2 */
void vApplicationIdleHook( void )
{
   /* vApplicationIdleHook() will only be called if configUSE_IDLE_HOOK is set
   to 1 in FreeRTOSConfig.h. It will be called on each iteration of the idle
   task. It is essential that code added to this hook function never attempts
   to block in any way (for example, call xQueueReceive() with a block time
   specified, or call vTaskDelay()). If the application makes use of the
   vTaskDelete() API function (as this demo application does) then it is also
   important that vApplicationIdleHook() is permitted to return to its calling
   function, because it is the responsibility of the idle task to clean up
   memory allocated by the kernel to any task that has since been deleted. */
}
/* USER CODE END 2 */

/* USER CODE BEGIN 4 */
void vApplicationStackOverflowHook(xTaskHandle xTask, signed char *pcTaskName)
{
   /* Run time stack overflow checking is performed if
   configCHECK_FOR_STACK_OVERFLOW is defined to 1 or 2. This hook function is
   called if a stack overflow is detected. */
}
/* USER CODE END 4 */
